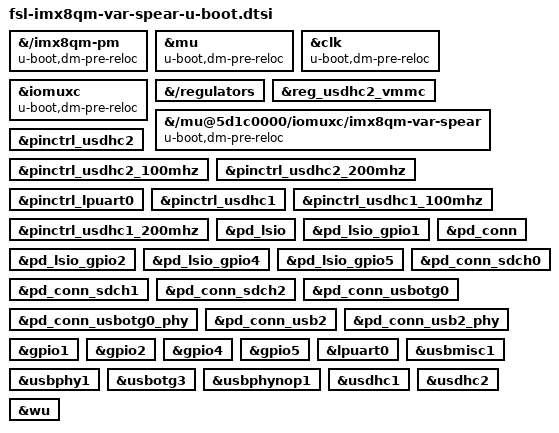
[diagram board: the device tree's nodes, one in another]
// SPDX-License-Identifier: GPL-2.0+
/*
 * Copyright 2018 NXP
 * Copyright 2020 Variscite Ltd.
 */

&{/imx8qm-pm} {
	u-boot,dm-spl;
	u-boot,dm-pre-reloc;
};

&mu {
	u-boot,dm-spl;
	u-boot,dm-pre-reloc;
};

&clk {
	u-boot,dm-spl;
	u-boot,dm-pre-reloc;
};

&iomuxc {
	u-boot,dm-spl;
	u-boot,dm-pre-reloc;
};

&{/regulators} {
	u-boot,dm-spl;
};

&reg_usdhc2_vmmc {
	u-boot,dm-spl;
};

&{/mu@5d1c0000/iomuxc/imx8qm-var-spear} {
	u-boot,dm-spl;
	u-boot,dm-pre-reloc;
};

&pinctrl_usdhc2 {
	u-boot,dm-spl;
};

&pinctrl_usdhc2_100mhz {
	u-boot,dm-spl;
};

&pinctrl_usdhc2_200mhz {
	u-boot,dm-spl;
};

&pinctrl_lpuart0 {
	u-boot,dm-spl;
};

&pinctrl_usdhc1 {
	u-boot,dm-spl;
};

&pinctrl_usdhc1_100mhz {
	u-boot,dm-spl;
};

&pinctrl_usdhc1_200mhz {
	u-boot,dm-spl;
};

&pd_lsio {
	u-boot,dm-spl;
};

&pd_lsio_gpio1 {
	u-boot,dm-spl;
};

&pd_lsio_gpio2 {
	u-boot,dm-spl;
};

&pd_lsio_gpio4 {
	u-boot,dm-spl;
};

&pd_lsio_gpio5 {
	u-boot,dm-spl;
};

&pd_conn {
	u-boot,dm-spl;
};

&pd_conn_sdch0 {
	u-boot,dm-spl;
};

&pd_conn_sdch1 {
	u-boot,dm-spl;
};

&pd_conn_sdch2 {
	u-boot,dm-spl;
};

&pd_conn_usbotg0 {
	u-boot,dm-spl;
};

&pd_conn_usbotg0_phy {
	u-boot,dm-spl;
};

&pd_conn_usb2 {
	u-boot,dm-spl;
};

&pd_conn_usb2_phy {
	u-boot,dm-spl;
};

&gpio1 {
	u-boot,dm-spl;
};

&gpio2 {
	u-boot,dm-spl;
};

&gpio4 {
	u-boot,dm-spl;
};

&gpio5 {
	u-boot,dm-spl;
};

&lpuart0 {
	u-boot,dm-spl;
};

&usbmisc1 {
	u-boot,dm-spl;
};

&usbphy1 {
	u-boot,dm-spl;
};

&usbotg3 {
	u-boot,dm-spl;
};

&usbphynop1 {
	u-boot,dm-spl;
};

&usdhc1 {
	u-boot,dm-spl;
};

&usdhc2 {
	u-boot,dm-spl;
};

&wu {
	u-boot,dm-spl;
};
